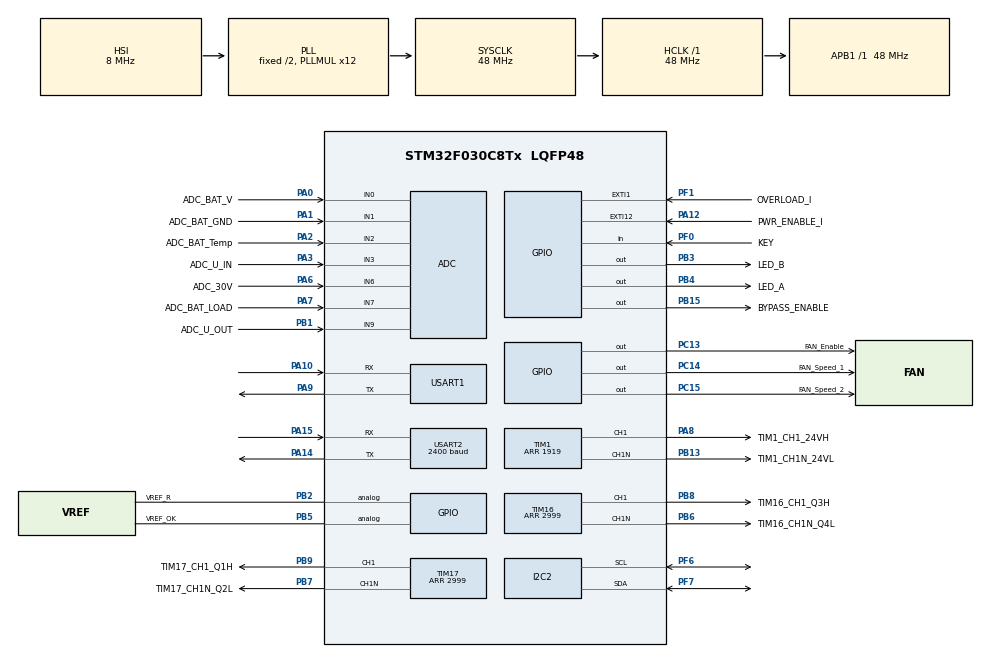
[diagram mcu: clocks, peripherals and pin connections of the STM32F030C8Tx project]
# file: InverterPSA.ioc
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I2C2.Timing=0x10805D88
Mcu.Family=STM32F0
Mcu.Name=STM32F030C8Tx
Mcu.Package=LQFP48
NVIC.TIM6_IRQn=true\:0\:0\:false\:false\:true\:true\:true\:true
PA0.GPIO_Label=ADC_BAT_V
PA0.Mode=IN0
PA0.Signal=ADC_IN0
PA1.GPIO_Label=ADC_BAT_GND
PA1.Mode=IN1
PA1.Signal=ADC_IN1
PA10.Mode=Asynchronous
PA10.Signal=USART1_RX
PA12.GPIO_Label=PWR_ENABLE_I
PA12.Signal=GPXTI12
PA13.Signal=SYS_SWDIO
PA14.Mode=Asynchronous
PA14.Signal=USART2_TX
PA15.Mode=Asynchronous
PA15.Signal=USART2_RX
PA2.GPIO_Label=ADC_BAT_Temp
PA2.Mode=IN2
PA2.Signal=ADC_IN2
PA3.GPIO_Label=ADC_U_IN
PA3.Mode=IN3
PA3.Signal=ADC_IN3
PA6.GPIO_Label=ADC_30V
PA6.Mode=IN6
PA6.Signal=ADC_IN6
PA7.GPIO_Label=ADC_BAT_LOAD
PA7.Mode=IN7
PA7.Signal=ADC_IN7
PA8.GPIO_Label=TIM1_CH1_24VH
PA8.Signal=S_TIM1_CH1
PA9.Mode=Asynchronous
PA9.Signal=USART1_TX
PB1.GPIO_Label=ADC_U_OUT
PB1.Mode=IN9
PB1.Signal=ADC_IN9
PB13.GPIO_Label=TIM1_CH1N_24VL
PB13.Mode=PWM Generation1 CH1 CH1N
PB13.Signal=TIM1_CH1N
PB15.GPIO_Label=BYPASS_ENABLE
PB15.Signal=GPIO_Output
PB2.GPIO_Label=VREF_R
PB2.Signal=GPIO_Analog
PB3.GPIO_Label=LED_B
PB3.Signal=GPIO_Output
PB4.GPIO_Label=LED_A
PB4.Signal=GPIO_Output
PB5.GPIO_Label=VREF_OK
PB5.Signal=GPIO_Analog
PB6.GPIO_Label=TIM16_CH1N_Q4L
PB6.Mode=PWM Generation1 CH1 CH1N
PB6.Signal=TIM16_CH1N
PB7.GPIO_Label=TIM17_CH1N_Q2L
PB7.Mode=PWM Generation1 CH1 CH1N
PB7.Signal=TIM17_CH1N
PB8.GPIO_Label=TIM16_CH1_Q3H
PB8.Signal=S_TIM16_CH1
PB9.GPIO_Label=TIM17_CH1_Q1H
PB9.Signal=S_TIM17_CH1
PC13.GPIO_Label=FAN_Enable
PC13.Signal=GPIO_Output
PC14-OSC32_IN.GPIO_Label=FAN_Speed_1
PC14-OSC32_IN.Signal=GPIO_Output
PC15-OSC32_OUT.GPIO_Label=FAN_Speed_2
PC15-OSC32_OUT.Signal=GPIO_Output
PF0-OSC_IN.GPIO_Label=KEY
PF0-OSC_IN.Signal=GPIO_Input
PF1-OSC_OUT.GPIO_Label=OVERLOAD_I
PF1-OSC_OUT.Signal=GPXTI1
PF6.Mode=I2C
PF6.Signal=I2C2_SCL
PF7.Mode=I2C
PF7.Signal=I2C2_SDA
ProjectManager.HeapSize=0x200
ProjectManager.StackSize=0x400
ProjectManager.TargetToolchain=STM32CubeIDE
RCC.AHBFreq_Value=48000000
RCC.APB1Freq_Value=48000000
RCC.APB1TimFreq_Value=48000000
RCC.HCLKFreq_Value=48000000
RCC.PLLMUL=RCC_PLL_MUL12
RCC.SYSCLKFreq_VALUE=48000000
RCC.SYSCLKSource=RCC_SYSCLKSOURCE_PLLCLK
SH.S_TIM16_CH1.0=TIM16_CH1,PWM Generation1 CH1 CH1N
SH.S_TIM17_CH1.0=TIM17_CH1,PWM Generation1 CH1 CH1N
SH.S_TIM1_CH1.0=TIM1_CH1,PWM Generation1 CH1 CH1N
TIM1.AutoReloadPreload=TIM_AUTORELOAD_PRELOAD_ENABLE
TIM1.AutomaticOutput=TIM_AUTOMATICOUTPUT_ENABLE
TIM1.Channel-PWM\ Generation1\ CH1\ CH1N=TIM_CHANNEL_1
TIM1.DeadTime=24
TIM1.OffStateIDLEMode=TIM_OSSI_ENABLE
TIM1.OffStateRunMode=TIM_OSSR_ENABLE
TIM1.Period=1919
TIM1.Pulse-PWM\ Generation1\ CH1\ CH1N=960
TIM16.AutoReloadPreload=TIM_AUTORELOAD_PRELOAD_ENABLE
TIM16.AutomaticOutput=TIM_AUTOMATICOUTPUT_ENABLE
TIM16.Channel=TIM_CHANNEL_1
TIM16.DeadTime=24
TIM16.OCMode_PWM=TIM_OCMODE_PWM2
TIM16.OffStateIDLEMode=TIM_OSSI_ENABLE
TIM16.OffStateRunMode=TIM_OSSR_ENABLE
TIM16.Period=2999
TIM16.Pulse=1499
TIM17.AutoReloadPreload=TIM_AUTORELOAD_PRELOAD_ENABLE
TIM17.AutomaticOutput=TIM_AUTOMATICOUTPUT_ENABLE
TIM17.Channel=TIM_CHANNEL_1
TIM17.DeadTime=24
TIM17.OffStateIDLEMode=TIM_OSSI_ENABLE
TIM17.OffStateRunMode=TIM_OSSR_ENABLE
TIM17.Period=2999
TIM17.Pulse=1499
TIM6.Period=199
TIM6.Prescaler=47
USART1.VirtualMode-Asynchronous=VM_ASYNC
USART2.BaudRate=2400
USART2.Mode=MODE_RX
USART2.VirtualMode-Asynchronous=VM_ASYNC
VP_TIM16_VS_ClockSourceINT.Mode=Enable_Timer
VP_TIM17_VS_ClockSourceINT.Mode=Enable_Timer
VP_TIM6_VS_ClockSourceINT.Mode=Enable_Timer
board=custom

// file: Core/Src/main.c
/* USER CODE BEGIN Header */
/**
  ******************************************************************************
  * @file           : main.c
  * @brief          : Main program body
  ******************************************************************************
  * @attention
  *
  * Copyright (c) 2025 STMicroelectronics.
  * All rights reserved.
  *
  * This software is licensed under terms that can be found in the LICENSE file
  * in the root directory of this software component.
  * If no LICENSE file comes with this software, it is provided AS-IS.
  *
  ******************************************************************************
  */
/* USER CODE END Header */
#include "main.h"
#include "adc.h"
#include "i2c.h"
#include "tim.h"
#include "usart.h"
#include "gpio.h"

/* USER CODE BEGIN Includes */
#include "gpio.h"
#include "sinegen.h"
/* USER CODE END Includes */

void SystemClock_Config(void);

/* USER CODE BEGIN 0 */
#define LED_A_PERIOD 1
#define LED_B_PERIOD 1000

/* USER CODE END 0 */

int main(void)
{

  /* MCU Configuration--------------------------------------------------------*/

  /* Reset of all peripherals, Initializes the Flash interface and the Systick. */
  HAL_Init();

  /* Configure the system clock */
  SystemClock_Config();

  /* Initialize all configured peripherals */
  MX_GPIO_Init();
  MX_ADC_Init();
  MX_I2C2_Init();
  MX_TIM1_Init();
  MX_TIM16_Init();
  MX_TIM17_Init();
  MX_USART1_UART_Init();
  MX_USART2_UART_Init();
  MX_TIM6_Init();

  /* Infinite loop */
  /* USER CODE BEGIN WHILE */

  uint32_t prevA = HAL_GetTick();
  uint32_t prevB = prevA;

  SineGen_Init();
  SineGen_Start();
 // Bridge_SoftStart();

  while (1)
  {
      uint32_t now = HAL_GetTick();

      // Задача «мигание LED A»
      if (now - prevA >= LED_A_PERIOD)
      {
          prevA = now;
          //HAL_GPIO_TogglePin(LED_A_GPIO_Port, LED_A_Pin);
      }

      // Задача «мигание LED B»
      if (now - prevB >= LED_B_PERIOD)
      {
          prevB = now;
          HAL_GPIO_TogglePin(LED_B_GPIO_Port, LED_B_Pin);
      }

      // Здесь можно добавить другую логику — ни одна из «задач» не блокирует петлю

    /* USER CODE END WHILE */

  }
}

void SystemClock_Config(void)
{
  RCC_OscInitTypeDef RCC_OscInitStruct = {0};
  RCC_ClkInitTypeDef RCC_ClkInitStruct = {0};
  RCC_PeriphCLKInitTypeDef PeriphClkInit = {0};

  /** Initializes the RCC Oscillators according to the specified parameters
  * in the RCC_OscInitTypeDef structure.
  */
  RCC_OscInitStruct.OscillatorType = RCC_OSCILLATORTYPE_HSI|RCC_OSCILLATORTYPE_HSI14;
  RCC_OscInitStruct.HSIState = RCC_HSI_ON;
  RCC_OscInitStruct.HSI14State = RCC_HSI14_ON;
  RCC_OscInitStruct.HSICalibrationValue = RCC_HSICALIBRATION_DEFAULT;
  RCC_OscInitStruct.HSI14CalibrationValue = 16;
  RCC_OscInitStruct.PLL.PLLState = RCC_PLL_ON;
  RCC_OscInitStruct.PLL.PLLSource = RCC_PLLSOURCE_HSI;
  RCC_OscInitStruct.PLL.PLLMUL = RCC_PLL_MUL12;
  RCC_OscInitStruct.PLL.PREDIV = RCC_PREDIV_DIV1;
  if (HAL_RCC_OscConfig(&RCC_OscInitStruct) != HAL_OK)
  {
    Error_Handler();
  }

  /** Initializes the CPU, AHB and APB buses clocks
  */
  RCC_ClkInitStruct.ClockType = RCC_CLOCKTYPE_HCLK|RCC_CLOCKTYPE_SYSCLK
                              |RCC_CLOCKTYPE_PCLK1;
  RCC_ClkInitStruct.SYSCLKSource = RCC_SYSCLKSOURCE_PLLCLK;
  RCC_ClkInitStruct.AHBCLKDivider = RCC_SYSCLK_DIV1;
  RCC_ClkInitStruct.APB1CLKDivider = RCC_HCLK_DIV1;

  if (HAL_RCC_ClockConfig(&RCC_ClkInitStruct, FLASH_LATENCY_1) != HAL_OK)
  {
    Error_Handler();
  }
  PeriphClkInit.PeriphClockSelection = RCC_PERIPHCLK_USART1;
  PeriphClkInit.Usart1ClockSelection = RCC_USART1CLKSOURCE_PCLK1;
  if (HAL_RCCEx_PeriphCLKConfig(&PeriphClkInit) != HAL_OK)
  {
    Error_Handler();
  }
}

void Error_Handler(void)
{
  __disable_irq();
  while (1)
  {
  }
}
